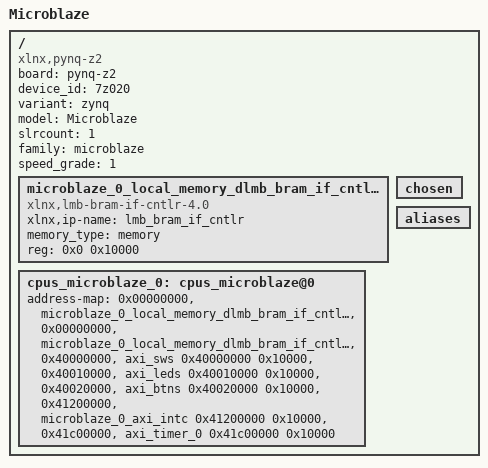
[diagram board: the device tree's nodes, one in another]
/dts-v1/;
#include "pl.dtsi"
/ {
	board = "pynq-z2";
	compatible = "xlnx,pynq-z2";
	device_id = "7z020";
	#address-cells = <1>;
	variant = "zynq";
	model = "Microblaze";
	#size-cells = <1>;
	slrcount = <1>;
	family = "microblaze";
	speed_grade = "1";
	microblaze_0_local_memory_dlmb_bram_if_cntlr_memory: memory@0 {
		compatible = "xlnx,lmb-bram-if-cntlr-4.0";
		xlnx,ip-name = "lmb_bram_if_cntlr";
		device_type = "memory";
		memory_type = "memory";
		reg = <0x0 0x10000>;
	};
	chosen {
	};
	aliases {
	};
	cpus_microblaze_0: cpus_microblaze@0 {
		address-map = <0x00000000 &microblaze_0_local_memory_dlmb_bram_if_cntlr_memory 0x00000000 0x10000>, 
			      <0x00000000 &microblaze_0_local_memory_dlmb_bram_if_cntlr 0x00000000 0x10000>, 
			      <0x40000000 &axi_sws 0x40000000 0x10000>, 
			      <0x40010000 &axi_leds 0x40010000 0x10000>, 
			      <0x40020000 &axi_btns 0x40020000 0x10000>, 
			      <0x41200000 &microblaze_0_axi_intc 0x41200000 0x10000>, 
			      <0x41c00000 &axi_timer_0 0x41c00000 0x10000>;
		#ranges-address-cells = <0x1>;
		#ranges-size-cells = <0x1>;
	};
};
